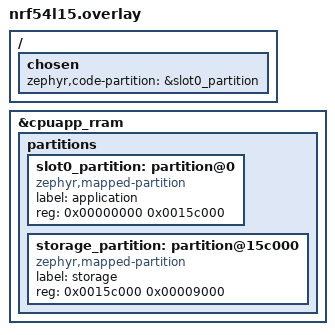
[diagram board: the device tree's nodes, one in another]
/ {
	chosen {
		zephyr,code-partition = &slot0_partition;
	};
};

&cpuapp_rram {
	/delete-node/ partitions;

	partitions {
		ranges;
		#address-cells = <1>;
		#size-cells = <1>;

		slot0_partition: partition@0 {
			compatible = "zephyr,mapped-partition";
			label = "application";
			reg = <0x00000000 0x0015c000>;
		};

		storage_partition: partition@15c000 {
			compatible = "zephyr,mapped-partition";
			label = "storage";
			reg = <0x0015c000 0x00009000>;
		};
	};
};
